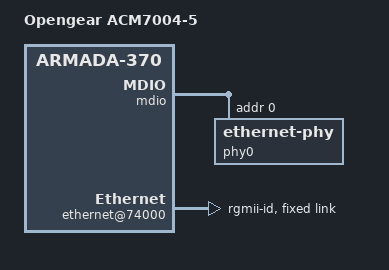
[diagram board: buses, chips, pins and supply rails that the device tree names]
/*
 * Device Tree file for Opengear ACM7004-5
 *
 * Ken Wilson <ken.wilson@opengear.com>
 *
 * This file is licensed under the terms of the GNU General Public
 * License version 2.  This program is licensed "as is" without any
 * warranty of any kind, whether express or implied.
 */
 /dts-v1/;
 /include/ "armada-370-acm7000.dtsi"

 / {
	model = "Opengear ACM7004-5";
	compatible = "opengear,cm7000", "marvell,armada370", "marvell,armada-370-xp";
	
	soc {
		internal-regs {
			mdio {	
				phy0: ethernet-phy@0 {
					reg = <0>;
					marvell,reg-init = <18 20 0xffff 0x0226>;
				};
			};
			
			ethernet@74000 {
				status = "okay";
				phy-mode = "rgmii-id";
				pinctrl-0 = <&ge1_pins>;
				pinctrl-names = "default";
				fixed-link {
					speed = <1000>;
					full-duplex;
				};
			};
		};
	};
 };


